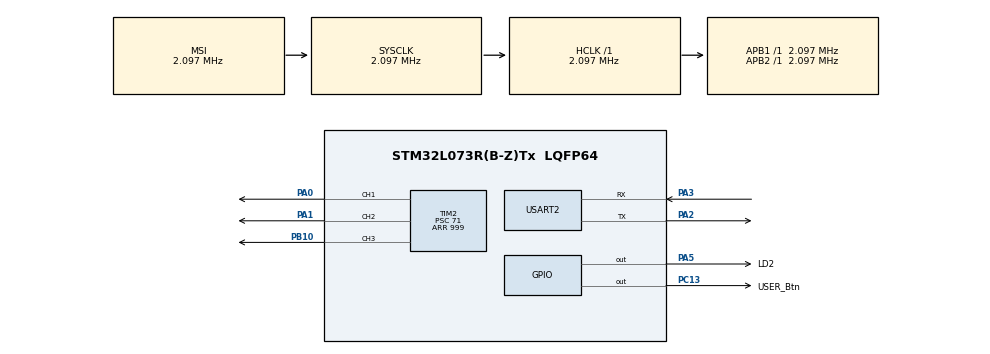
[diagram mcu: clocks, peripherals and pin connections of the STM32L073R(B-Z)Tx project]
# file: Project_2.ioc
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Mcu.Family=STM32L0
Mcu.Name=STM32L073R(B-Z)Tx
Mcu.Package=LQFP64
NVIC.TIM2_IRQn=true\:0\:0\:false\:false\:true\:true\:true\:true
NVIC.USART2_IRQn=true\:0\:0\:false\:false\:true\:true\:true\:true
PA0.Signal=S_TIM2_CH1
PA1.Signal=S_TIM2_CH2
PA2.Mode=Asynchronous
PA2.Signal=USART2_TX
PA3.Mode=Asynchronous
PA3.Signal=USART2_RX
PA5.GPIO_Label=LD2
PA5.Signal=GPIO_Output
PB10.Signal=S_TIM2_CH3
PB3.Signal=TSC_G5_IO1
PC13.GPIO_Label=USER_Btn
PC13.Signal=GPIO_Output
ProjectManager.HeapSize=0x200
ProjectManager.StackSize=0x400
ProjectManager.TargetToolchain=STM32CubeIDE
RCC.AHBFreq_Value=2097000
RCC.APB1Freq_Value=2097000
RCC.APB1TimFreq_Value=2097000
RCC.APB2Freq_Value=2097000
RCC.APB2TimFreq_Value=2097000
RCC.HSE_VALUE=8000000
RCC.HSI16_VALUE=16000000
RCC.HSI48_VALUE=48000000
RCC.HSI_VALUE=16000000
RCC.LSE_VALUE=32768
RCC.MSI_VALUE=2097000
RCC.SYSCLKFreq_VALUE=2097000
RCC.VCOOutputFreq_Value=48000000
SH.S_TIM2_CH1.0=TIM2_CH1,PWM Generation1 CH1
SH.S_TIM2_CH2.0=TIM2_CH2,PWM Generation2 CH2
SH.S_TIM2_CH3.0=TIM2_CH3,PWM Generation3 CH3
TIM2.Channel-PWM\ Generation1\ CH1=TIM_CHANNEL_1
TIM2.Channel-PWM\ Generation2\ CH2=TIM_CHANNEL_2
TIM2.Channel-PWM\ Generation3\ CH3=TIM_CHANNEL_3
TIM2.Period=999
TIM2.Prescaler=71
TIM2.Pulse-PWM\ Generation2\ CH2=500
TIM2.Pulse-PWM\ Generation3\ CH3=500
USART2.VirtualMode-Asynchronous=VM_ASYNC
VP_TIM2_VS_ClockSourceINT.Mode=Internal
board=custom

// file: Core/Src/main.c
/* USER CODE BEGIN Header */
/**
  ******************************************************************************
  * @file           : main.c
  * @brief          : Main program body
  ******************************************************************************
  * @attention
  *
  * Copyright (c) 2023 STMicroelectronics.
  * All rights reserved.
  *
  * This software is licensed under terms that can be found in the LICENSE file
  * in the root directory of this software component.
  * If no LICENSE file comes with this software, it is provided AS-IS.
  *
  ******************************************************************************
  */
/* USER CODE END Header */
#include "main.h"
#include "tim.h"
#include "usart.h"
#include "gpio.h"

/* USER CODE BEGIN Includes */
	#include "led_config.h"
	#include "btn_config.h"
#include "encoder_config.h"
/* USER CODE END Includes */

/* USER CODE BEGIN PV */
unsigned int cnt = 0;
/* USER CODE END PV */

void SystemClock_Config(void);

int main(void)
{

  /* MCU Configuration--------------------------------------------------------*/

  /* Reset of all peripherals, Initializes the Flash interface and the Systick. */
  HAL_Init();

  /* Configure the system clock */
  SystemClock_Config();

  /* Initialize all configured peripherals */
  MX_GPIO_Init();
  MX_TIM2_Init();
  MX_USART2_UART_Init();
  /* USER CODE BEGIN 2 */
  //HAL_TIM_Base_Start(&htim2);
   //_Bool LD1_State;
   //HAL_TIM_Base_Start_IT(&htim2);
   //HAL_UART_Receive_IT(&huart2, (uint8_t*)msg, TIM2_MSG_LEN);
  LED_PWM_Init(&hledr);
    LED_PWM_Init(&hledg);
    LED_PWM_Init(&hledb);

  /* USER CODE END 2 */

  /* Infinite loop */
  /* USER CODE BEGIN WHILE */
  while (1)
  {
	  //cnt = ENC_GetCounter(&henc1);

	      LED_PWM_WriteDuty(&hledg, 0.0f);
	      LED_PWM_WriteDuty(&hledr, 0.0f);
	      LED_PWM_WriteDuty(&hledb, 100.0f);

	 // cnt = cnt + 10;
	   //  LED_PWM_WriteDuty(&hledr,  cnt);
	   //  LED_PWM_WriteDuty(&hledr,  100.f);
	   //  HAL_Delay(500);
	   //  if(cnt >= 100)
	   //  {
	    //	 cnt = 0;
	   //  }
//
	  	  //zad 1
	  //if(__HAL_TIM_GET_FLAG(&htim2, TIM_FLAG_UPDATE))
	    //  {
	    //    __HAL_TIM_CLEAR_FLAG(&htim2, TIM_FLAG_UPDATE);
	    //    LED_GPIO_Toggle(&hld1);
	   //     LD1_State = LED_GPIO_Read(&hld1);
	   //   }
    /* USER CODE END WHILE */

  }
}

void SystemClock_Config(void)
{
  RCC_OscInitTypeDef RCC_OscInitStruct = {0};
  RCC_ClkInitTypeDef RCC_ClkInitStruct = {0};
  RCC_PeriphCLKInitTypeDef PeriphClkInit = {0};

  /** Configure the main internal regulator output voltage
  */
  __HAL_PWR_VOLTAGESCALING_CONFIG(PWR_REGULATOR_VOLTAGE_SCALE1);

  /** Initializes the RCC Oscillators according to the specified parameters
  * in the RCC_OscInitTypeDef structure.
  */
  RCC_OscInitStruct.OscillatorType = RCC_OSCILLATORTYPE_MSI;
  RCC_OscInitStruct.MSIState = RCC_MSI_ON;
  RCC_OscInitStruct.MSICalibrationValue = 0;
  RCC_OscInitStruct.MSIClockRange = RCC_MSIRANGE_5;
  RCC_OscInitStruct.PLL.PLLState = RCC_PLL_NONE;
  if (HAL_RCC_OscConfig(&RCC_OscInitStruct) != HAL_OK)
  {
    Error_Handler();
  }

  /** Initializes the CPU, AHB and APB buses clocks
  */
  RCC_ClkInitStruct.ClockType = RCC_CLOCKTYPE_HCLK|RCC_CLOCKTYPE_SYSCLK
                              |RCC_CLOCKTYPE_PCLK1|RCC_CLOCKTYPE_PCLK2;
  RCC_ClkInitStruct.SYSCLKSource = RCC_SYSCLKSOURCE_MSI;
  RCC_ClkInitStruct.AHBCLKDivider = RCC_SYSCLK_DIV1;
  RCC_ClkInitStruct.APB1CLKDivider = RCC_HCLK_DIV1;
  RCC_ClkInitStruct.APB2CLKDivider = RCC_HCLK_DIV1;

  if (HAL_RCC_ClockConfig(&RCC_ClkInitStruct, FLASH_LATENCY_0) != HAL_OK)
  {
    Error_Handler();
  }
  PeriphClkInit.PeriphClockSelection = RCC_PERIPHCLK_USART2;
  PeriphClkInit.Usart2ClockSelection = RCC_USART2CLKSOURCE_PCLK1;
  if (HAL_RCCEx_PeriphCLKConfig(&PeriphClkInit) != HAL_OK)
  {
    Error_Handler();
  }
}

void Error_Handler(void)
{
  __disable_irq();
  while (1)
  {
  }
}
